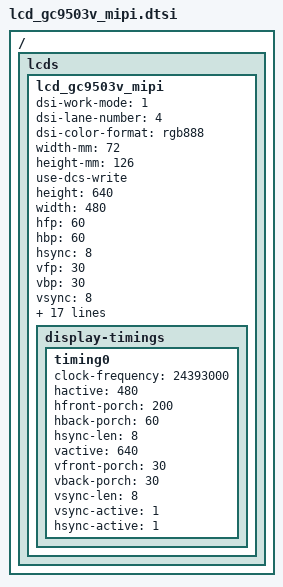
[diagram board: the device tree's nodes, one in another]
// SPDX-License-Identifier: GPL-2.0

/ { lcds {
	lcd_gc9503v_mipi: lcd_gc9503v_mipi {
		dsi-work-mode = <1>; /* video burst mode*/
		dsi-lane-number = <4>;
		dsi-color-format = "rgb888";
		width-mm = <72>;
		height-mm = <126>;
		use-dcs-write;

		/*mipi info*/
		height = <640>;
		width = <480>;
		hfp = <60>;
		hbp = <60>;
		hsync = <8>;
		vfp = <30>;
		vbp = <30>;
		vsync = <8>;
		fps = <60>;
		work-mode = <0>;
		rgb-mode = <3>;
		lane-number = <2>;
		phy-bit-clock = <341000000>;
		split-enable = <0>;
		eotp-enable = <0>;
		burst-mode = <2>;
		esd-check-enable = <0>;
		/* DSI_CMD, DSI_MODE, timeout, len, cmd  */
		initial-command = [
			39 01 00 06 F0 55 AA 52 08 00
			39 01 00 03 F6 5A 87
			39 01 00 02 C1 3F
			39 01 00 02 C2 0E
			39 01 00 02 C6 F8
			39 01 00 02 C9 10
			39 01 00 02 CD 25
			39 01 00 04 FA 08 08 08
			39 01 00 02 F8 8A
			39 01 00 02 71 48
			39 01 00 02 72 48
			39 01 00 03 73 00 44
			39 01 00 02 97 EE
			39 01 00 02 83 93
			39 01 00 02 A3 22
			39 01 00 04 FD 28 3C 00
			39 01 00 02 AC 65
			39 01 00 02 A7 47
			39 01 00 02 A0 DD
			39 01 00 02 9A C0
			39 01 00 02 9B 40
			39 01 00 03 82 3E 3E
			39 01 00 02 B1 10
			39 01 00 03 7A 13 1A
			39 01 00 03 7B 13 1A
			39 01 00 21 6D 00 1F 19 1A 10 0E 0C 0A 02 08 1E 1E 1E 1E 1E 1E 1E 1E 1E 1E 1E 1E 07 01 09 0B 0D 0F 1A 19 1F 00
			39 01 00 11 64 28 04 02 7C 03 03 28 03 02 7D 03 03 7A 7A 7A 7A
			39 01 00 11 65 28 02 02 7E 03 03 28 01 02 7F 03 03 7A 7A 7A 7A
			39 01 00 11 66 28 00 02 80 03 03 20 01 02 81 03 03 7A 7A 7A 7A
			39 01 00 11 67 20 02 02 82 03 03 20 03 02 83 03 03 7A 7A 7A 7A
			39 01 00 0e 68 77 08 06 08 05 7A 7A 08 06 08 05 7A 7A
			39 01 00 09 60 28 06 7A 7A 28 05 7A 7A
			39 01 00 09 63 22 7E 7A 7A 22 7F 7A 7A
			39 01 00 08 69 14 22 14 22 14 22 08
			39 01 00 02 6B 07
			39 01 00 35 D1 00 00 00 80 00 BF 00 F8 01 20 01 4D 01 68 01 88 01 B8 01 F0 02 28 02 7D 02 B8 02 BA 03 00 03 4D 03 6A 03 88 03 A0 03 B5 03 C8 03 D0 03 E8 03 F0 03 F8 03 FF
			39 01 00 35 D2 00 00 00 80 00 BF 00 F8 01 20 01 4D 01 68 01 88 01 B8 01 F0 02 28 02 7D 02 B8 02 BA 03 00 03 4D 03 6A 03 88 03 A0 03 B5 03 C8 03 D0 03 E8 03 F0 03 F8 03 FF
			39 01 00 35 D3 00 00 00 80 00 BF 00 F8 01 20 01 4D 01 68 01 88 01 B8 01 F0 02 28 02 7D 02 B8 02 BA 03 00 03 4D 03 6A 03 88 03 A0 03 B5 03 C8 03 D0 03 E8 03 F0 03 F8 03 FF
			39 01 00 35 D4 00 00 00 80 00 BF 00 F8 01 20 01 4D 01 68 01 88 01 B8 01 F0 02 28 02 7D 02 B8 02 BA 03 00 03 4D 03 6A 03 88 03 A0 03 B5 03 C8 03 D0 03 E8 03 F0 03 F8 03 FF
			39 01 00 35 D5 00 00 00 80 00 BF 00 F8 01 20 01 4D 01 68 01 88 01 B8 01 F0 02 28 02 7D 02 B8 02 BA 03 00 03 4D 03 6A 03 88 03 A0 03 B5 03 C8 03 D0 03 E8 03 F0 03 F8 03 FF
			39 01 00 35 D6 00 00 00 80 00 BF 00 F8 01 20 01 4D 01 68 01 88 01 B8 01 F0 02 28 02 7D 02 B8 02 BA 03 00 03 4D 03 6A 03 88 03 A0 03 B5 03 C8 03 D0 03 E8 03 F0 03 F8 03 FF
			39 01 78 02 11 00
			39 01 14 02 29 00
		];
		sleep-in-command = [
			39 01 14 01 28
			39 01 78 01 10
		];
		sleep-out-command = [
			05 01 78 01 11
			05 01 14 01 29
		];
		read-id-command = [
			37 01 00 01 01
			14 01 00 01 04
		];
		display-timings {
			timing0 {
				clock-frequency = <24393000>;
				hactive = <480>;
				hfront-porch = <200>;
				hback-porch = <60>;
				hsync-len = <8>;
				vactive = <640>;
				vfront-porch = <30>;
				vback-porch = <30>;
				vsync-len = <8>;
				vsync-active = <1>;
				hsync-active = <1>;
			};
		};
	};
};};
